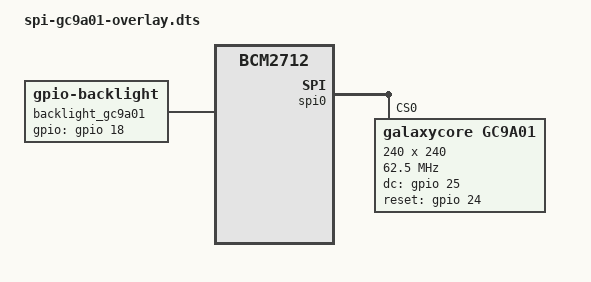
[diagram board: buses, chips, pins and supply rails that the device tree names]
// Raspberry Pi 5 - GC9A01 Round Display
// Device Tree Overlay for GC9A01 SPI round displays
// Copyright (C) 2025 The Android Open Source Project

/dts-v1/;
/plugin/;

// ============================================================================
// GC9A01 1.28" Round Display (240x240)
// ============================================================================
/ {
    compatible = "brcm,bcm2712";
    
    fragment@0 {
        target = <&spi0>;
        __overlay__ {
            status = "okay";
            #address-cells = <1>;
            #size-cells = <0>;
            
            gc9a01: gc9a01@0 {
                compatible = "galaxycore,gc9a01";
                reg = <0>;
                spi-max-frequency = <62500000>;
                
                dc-gpios = <&gpio 25 0>;
                reset-gpios = <&gpio 24 0>;
                
                width = <240>;
                height = <240>;
                buswidth = <8>;
                fps = <60>;
            };
        };
    };
    
    fragment@1 {
        target = <&gpio>;
        __overlay__ {
            gc9a01_pins: gc9a01_pins {
                brcm,pins = <24 25 18>;
                brcm,function = <1 1 1>;
            };
        };
    };
    
    fragment@2 {
        target-path = "/";
        __overlay__ {
            backlight_gc9a01: backlight {
                compatible = "gpio-backlight";
                gpios = <&gpio 18 0>;
                default-on;
            };
        };
    };
};
